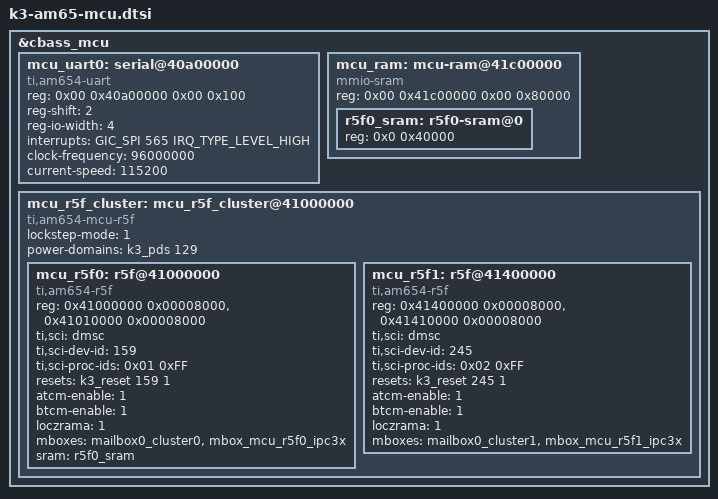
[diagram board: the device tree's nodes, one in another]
// SPDX-License-Identifier: GPL-2.0
/*
 * Device Tree Source for AM6 SoC Family MCU Domain peripherals
 *
 * Copyright (C) 2016-2018 Texas Instruments Incorporated - http://www.ti.com/
 */

&cbass_mcu {
	mcu_uart0: serial@40a00000 {
		compatible = "ti,am654-uart";
			reg = <0x00 0x40a00000 0x00 0x100>;
			reg-shift = <2>;
			reg-io-width = <4>;
			interrupts = <GIC_SPI 565 IRQ_TYPE_LEVEL_HIGH>;
			clock-frequency = <96000000>;
			current-speed = <115200>;
	};

	mcu_ram: mcu-ram@41c00000 {
		compatible = "mmio-sram";
		reg = <0x00 0x41c00000 0x00 0x80000>;
		ranges = <0x0 0x00 0x41c00000 0x80000>;
		#address-cells = <1>;
		#size-cells = <1>;

		r5f0_sram: r5f0-sram@0 {
			reg = <0x0 0x40000>;
		};
	};

	mcu_r5f_cluster: mcu_r5f_cluster@41000000 {
		compatible = "ti,am654-mcu-r5f";
		lockstep-mode = <1>;
		#address-cells = <1>;
		#size-cells = <1>;
		ranges = <0x41000000 0x00 0x41000000 0x20000>,
			 <0x41400000 0x00 0x41400000 0x20000>;
		power-domains = <&k3_pds 129>;

		mcu_r5f0: r5f@41000000 {
			compatible = "ti,am654-r5f";
			reg = <0x41000000 0x00008000>,
			      <0x41010000 0x00008000>;
			reg-names = "atcm", "btcm";
			ti,sci = <&dmsc>;
			ti,sci-dev-id = <159>;
			ti,sci-proc-ids = <0x01 0xFF>;
			resets = <&k3_reset 159 1>;
			atcm-enable = <1>;
			btcm-enable = <1>;
			loczrama = <1>;
			mboxes = <&mailbox0_cluster0 &mbox_mcu_r5f0_ipc3x>;
			sram = <&r5f0_sram>;
		};

		mcu_r5f1: r5f@41400000 {
			compatible = "ti,am654-r5f";
			reg = <0x41400000 0x00008000>,
			      <0x41410000 0x00008000>;
			reg-names = "atcm", "btcm";
			ti,sci = <&dmsc>;
			ti,sci-dev-id = <245>;
			ti,sci-proc-ids = <0x02 0xFF>;
			resets = <&k3_reset 245 1>;
			atcm-enable = <1>;
			btcm-enable = <1>;
			loczrama = <1>;
			mboxes = <&mailbox0_cluster1 &mbox_mcu_r5f1_ipc3x>;
		};
	};
};
